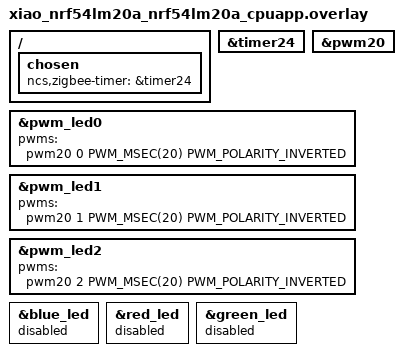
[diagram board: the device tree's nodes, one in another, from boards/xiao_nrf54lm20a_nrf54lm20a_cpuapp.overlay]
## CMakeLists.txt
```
cmake_minimum_required(VERSION 3.20.0)
find_package(Zephyr REQUIRED HINTS $ENV{ZEPHYR_BASE})
project(sustain_zigbee_node)
target_include_directories(app PRIVATE include)
target_sources(app PRIVATE src/main.c src/observation.c src/simulated_source.c
  src/zigbee_transport.c src/board_status.c)
```

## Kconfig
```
mainmenu "Sustain Zigbee test node"
source "Kconfig.zephyr"

config SUSTAIN_REPORT_INTERVAL_SECONDS
	int "Simulated observation interval in seconds"
	range 2 3600
	default 10

config SUSTAIN_STATUS_RGB
	bool "RGB PWM network indicator"
	depends on PWM
	default n

config SUSTAIN_SLEEPY
	bool "Sleepy receiver behavior"
	depends on ZIGBEE_ROLE_END_DEVICE
	default n
```

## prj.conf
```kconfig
CONFIG_ZIGBEE_ADD_ON=y
CONFIG_ZIGBEE_APP_UTILS=y
CONFIG_ZIGBEE_FACTORY_RESET=n
CONFIG_ZIGBEE_CHANNEL_SELECTION_MODE_MULTI=y
CONFIG_ZIGBEE_CHANNEL_MASK=0x07fff800
CONFIG_LTO=y
CONFIG_USE_DT_CODE_PARTITION=y
CONFIG_HEAP_MEM_POOL_SIZE=2048
CONFIG_MAIN_STACK_SIZE=2048
CONFIG_MAIN_THREAD_PRIORITY=7
CONFIG_SYSTEM_WORKQUEUE_STACK_SIZE=2048
CONFIG_LOG=y
CONFIG_LOG_MODE_DEFERRED=y
CONFIG_SERIAL=y
CONFIG_CONSOLE=y
CONFIG_UART_CONSOLE=y
```

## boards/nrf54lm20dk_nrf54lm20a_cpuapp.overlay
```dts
#include <nrf54lm20_cpuapp_partitions.dtsi>
/ { chosen { ncs,zigbee-timer = &timer24; }; };
&timer24 { status = "okay"; };
```

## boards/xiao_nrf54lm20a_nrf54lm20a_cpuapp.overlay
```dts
/* Tested xiao_source mapping: red=CH0/P1.22, blue=CH1/P1.23,
 * green=CH2/P1.24, active low. Pin control is supplied by pinned Seeed BSP.
 * This is a direct-programming development image; no MCUboot/USB DFU.
 */
#include <nrf54lm20_cpuapp_partitions.dtsi>

/* Seeed also declares non-secure upgrade partitions: remove overlaps. */
/delete-node/ &slot0_ns_partition;
/delete-node/ &slot1_ns_partition;

/ {
	chosen { ncs,zigbee-timer = &timer24; };
};
&timer24 { status = "okay"; };
&pwm20 { status = "okay"; };
&pwm_led0 { pwms = <&pwm20 0 PWM_MSEC(20) PWM_POLARITY_INVERTED>; };
&pwm_led1 { pwms = <&pwm20 1 PWM_MSEC(20) PWM_POLARITY_INVERTED>; };
&pwm_led2 { pwms = <&pwm20 2 PWM_MSEC(20) PWM_POLARITY_INVERTED>; };

/* PWM owns these pins; do not let gpio-leds drive the same outputs. */
&blue_led { status = "disabled"; };
&red_led { status = "disabled"; };
&green_led { status = "disabled"; };
```

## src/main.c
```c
/** @file
 * @brief Compose the simulated producer, optional indicator and transport.
 */
#include <zephyr/kernel.h>
#include <zephyr/logging/log.h>
#include "board_status.h"
#include "zigbee_transport.h"

LOG_MODULE_REGISTER(sustain_node, LOG_LEVEL_INF);

int main(void)
{
	int err = board_status_init();
	if (err) {
		LOG_ERR("Status indicator unavailable: %d", err);
		return err;
	}
	LOG_INF("SIMULATED observations; interval=%d s; role=%s",
		CONFIG_SUSTAIN_REPORT_INTERVAL_SECONDS,
		IS_ENABLED(CONFIG_SUSTAIN_SLEEPY) ? "sleepy end device" : "router");
	zigbee_transport_start();
	for (;;) {
		struct observation value = simulated_source_next(
			(uint32_t)(k_uptime_get() / 1000),
			IS_ENABLED(CONFIG_SUSTAIN_SLEEPY) ? 2 : 1);
		err = zigbee_transport_submit(&value);
		LOG_INF("Generated seq=%u simulated=1 enqueue=%d", value.sequence, err);
		k_sleep(K_SECONDS(CONFIG_SUSTAIN_REPORT_INTERVAL_SECONDS));
	}
}
```

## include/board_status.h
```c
/** @file
 * @brief Optional board-profile status indicator, independent of report logic.
 */
#ifndef SUSTAIN_BOARD_STATUS_H
#define SUSTAIN_BOARD_STATUS_H
#include <stdbool.h>
/**
 * @brief Initialize optional PWM indicators and show the unjoined state.
 * @retval 0 Initialization succeeded, or RGB support is disabled.
 * @retval -ENODEV A configured PWM device is unavailable.
 * @return A PWM driver error if a pulse could not be configured.
 */
int board_status_init(void);

/**
 * @brief Update the optional blue/green connection indication.
 * @param joined True for joined (green), false for unjoined (blue).
 * @note No-op without RGB support. PWM update errors are deliberately ignored;
 * this debug indicator does not control commissioning or radio behavior.
 */
void board_status_joined(bool joined);
#endif
```

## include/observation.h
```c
/** @file
 * @brief Portable observation model, simulator and wire encoder.
 */
#ifndef SUSTAIN_OBSERVATION_H
#define SUSTAIN_OBSERVATION_H

#include <stddef.h>
#include <stdint.h>

#define OBSERVATION_WIRE_VERSION 1U /**< Supported wire schema. */
#define OBSERVATION_WIRE_SIZE 16U /**< Encoded record size, without ZCL length. */
#define OBSERVATION_FLAG_SIMULATED 0x01U /**< Data came from a synthetic source. */
#define OBSERVATION_FLAG_ANOMALY 0x02U /**< Producer classified an anomaly. */

/**
 * @brief Application snapshot independent of Zephyr, board and Zigbee types.
 *
 * This is an in-memory model. Use observation_encode() instead of casting it
 * to bytes; C structure layout is not the wire representation.
 */
struct observation {
	uint32_t sequence; /**< Generated counter; restarts at boot and wraps. */
	uint32_t uptime_s; /**< Seconds since boot, modulo 2^32. */
	uint16_t score_milli; /**< 0..1000; not a calibrated probability. */
	uint16_t direction_deg; /**< 0..359; synthetic in the test application. */
	uint8_t flags; /**< Combination of OBSERVATION_FLAG_*; other bits zero. */
	uint8_t role; /**< 1 = powered router; 2 = sleepy end device. */
};

/**
 * @brief Encode a validated snapshot as a fixed-size little-endian v1 record.
 * @param[in] value Snapshot to validate; never retained or modified.
 * @param[out] output Caller-owned buffer of at least OBSERVATION_WIRE_SIZE bytes.
 * @retval 0 Record written, including its zero reserved byte.
 * @retval -EINVAL Null pointer, invalid score/direction/role or reserved flag bits.
 * @note Validation completes before output is written. No heap or radio APIs.
 */
int observation_encode(const struct observation *value,
		       uint8_t output[OBSERVATION_WIRE_SIZE]);

/**
 * @brief Advance the deterministic, single-producer simulated source.
 * @param uptime_s Caller-supplied uptime in seconds.
 * @param role Caller-supplied role; use 1 or 2 for an encodable record.
 * @return New snapshot with simulated flag set; sequence starts at 1.
 * @note Uses a static counter; call from one producer thread. Score is 900 every
 * tenth generated record and 100 otherwise; direction cycles in 15-degree steps.
 */
struct observation simulated_source_next(uint32_t uptime_s, uint8_t role);

#endif
```

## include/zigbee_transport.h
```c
/** @file
 * @brief Application-thread interface to the ZBOSS observation transport.
 */
#ifndef SUSTAIN_ZIGBEE_TRANSPORT_H
#define SUSTAIN_ZIGBEE_TRANSPORT_H
#include "observation.h"
/**
 * @brief Register the endpoint, configure the selected role and enable Zigbee.
 * @note Call once during startup. Uses normal persisted ZBOSS network state;
 * starting does not establish that commissioning or joining has completed.
 */
void zigbee_transport_start(void);

/**
 * @brief Copy a validated observation into the thread-safe latest-value slot.
 * @param[in] value Snapshot to encode; the pointer is not retained.
 * @retval 0 A ZBOSS callback was scheduled; delivery is not guaranteed.
 * @retval -EINVAL The snapshot fails observation_encode() validation.
 * @retval -ENOTCONN Node is not joined; pending data is not updated.
 * @retval -EAGAIN Callback scheduling failed after updating the pending slot.
 * @note Call from an application thread. Packet APIs run only in ZBOSS context.
 * Accepted observations may coalesce while a transmission is in flight. There
 * is no offline history or application acknowledgement. A later periodic
 * submission retries scheduling; no automatic retry timer is installed here.
 */
int zigbee_transport_submit(const struct observation *value);
#endif
```

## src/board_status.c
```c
/** @file
 * @brief Device-tree PWM indicator or no-op implementation selected by profile.
 */
#include "board_status.h"
#include <zephyr/kernel.h>
#if defined(CONFIG_SUSTAIN_STATUS_RGB)
#include <zephyr/drivers/pwm.h>

static const struct pwm_dt_spec red = PWM_DT_SPEC_GET(DT_ALIAS(pwm_led0));
static const struct pwm_dt_spec blue = PWM_DT_SPEC_GET(DT_ALIAS(pwm_led1));
static const struct pwm_dt_spec green = PWM_DT_SPEC_GET(DT_ALIAS(pwm_led2));

int board_status_init(void)
{
	if (!pwm_is_ready_dt(&red) || !pwm_is_ready_dt(&blue) ||
	    !pwm_is_ready_dt(&green)) {
		return -ENODEV;
	}
	int err = pwm_set_pulse_dt(&red, 0);
	if (!err) { err = pwm_set_pulse_dt(&green, 0); }
	if (!err) { err = pwm_set_pulse_dt(&blue, blue.period / 16); }
	return err;
}

void board_status_joined(bool joined)
{
	/* Deliberately dim; this debug indicator is not a power measurement mode. */
	(void)pwm_set_pulse_dt(&blue, joined ? 0 : blue.period / 16);
	(void)pwm_set_pulse_dt(&green, joined ? green.period / 16 : 0);
}
#else
int board_status_init(void) { return 0; }
void board_status_joined(bool joined) { ARG_UNUSED(joined); }
#endif
```

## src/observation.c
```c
/** @file
 * @brief Range validation and explicit byte-wise observation encoding.
 */
#include "observation.h"
#include <errno.h>

static void put16(uint8_t *out, uint16_t value)
{
	out[0] = (uint8_t)value;
	out[1] = (uint8_t)(value >> 8);
}

static void put32(uint8_t *out, uint32_t value)
{
	put16(out, (uint16_t)value);
	put16(out + 2, (uint16_t)(value >> 16));
}

int observation_encode(const struct observation *value,
		       uint8_t output[OBSERVATION_WIRE_SIZE])
{
	if (value == NULL || output == NULL || value->score_milli > 1000 ||
	    value->direction_deg >= 360 || value->role < 1 || value->role > 2 ||
	    (value->flags & ~0x03U) != 0) {
		return -EINVAL;
	}
	output[0] = OBSERVATION_WIRE_VERSION;
	output[1] = value->flags;
	put32(output + 2, value->sequence);
	put32(output + 6, value->uptime_s);
	put16(output + 10, value->score_milli);
	put16(output + 12, value->direction_deg);
	output[14] = value->role;
	output[15] = 0; /* reserved */
	return 0;
}
```

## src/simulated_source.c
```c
/** @file
 * @brief Deterministic test observations; no acoustic input or inference.
 */
#include "observation.h"

struct observation simulated_source_next(uint32_t uptime_s, uint8_t role)
{
	static uint32_t sequence;
	const uint32_t current = ++sequence;
	const uint16_t score = (current % 10U == 0U) ? 900U : 100U;

	return (struct observation) {
		.sequence = current,
		.uptime_s = uptime_s,
		.score_milli = score,
		.direction_deg = (uint16_t)((current % 24U) * 15U),
		.flags = OBSERVATION_FLAG_SIMULATED |
			 ((score >= 800U) ? OBSERVATION_FLAG_ANOMALY : 0U),
		.role = role,
	};
}
```

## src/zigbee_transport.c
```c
/** @file
 * @brief ZBOSS endpoint registration, report scheduling and buffer ownership.
 *
 * Application threads encode into a spinlock-protected pending slot. ZBOSS
 * callbacks own in_flight, allocate the outgoing buffer and free it after
 * completion or immediate rejection. No persistent event queue is implemented.
 */
#include <errno.h>
#include <string.h>
#include <zephyr/kernel.h>
#include <zephyr/logging/log.h>
#include <zephyr/sys/atomic.h>
#include <zboss_api.h>
#include <zb_nrf_platform.h>
#include <zigbee/zigbee_app_utils.h>
#include "board_status.h"
#include "zigbee_transport.h"

LOG_MODULE_REGISTER(sustain_zigbee, LOG_LEVEL_INF);

#define NODE_ENDPOINT 10
#define OBS_CLUSTER 0xfc00
#define OBS_ATTRIBUTE 0x0000
/* This private cluster uses generic read/discover commands only. */
#define OBS_CLUSTER_SERVER_ROLE_INIT NULL
#define OBS_CLUSTER_CLIENT_ROLE_INIT NULL

static zb_uint8_t zcl_version = ZB_ZCL_VERSION;
static zb_uint8_t power_source;
static zb_uint16_t identify_time;
static zb_char_t manufacturer[] = "\x07" "Sustain";
static zb_char_t model[] = "\x0e" "SustainNode-v1";
/* Octet string: ZCL length byte followed by the versioned wire record. */
static zb_uint8_t observation_attr[1 + OBSERVATION_WIRE_SIZE] = { OBSERVATION_WIRE_SIZE };
static uint8_t pending[OBSERVATION_WIRE_SIZE];
static struct k_spinlock pending_lock;
static atomic_t joined;
static bool in_flight; /* Only touched in ZBOSS context. */

ZB_ZCL_START_DECLARE_ATTRIB_LIST(basic_attrs)
 ZB_ZCL_SET_ATTR_DESC(ZB_ZCL_ATTR_BASIC_ZCL_VERSION_ID, &zcl_version)
 ZB_ZCL_SET_ATTR_DESC(ZB_ZCL_ATTR_BASIC_POWER_SOURCE_ID, &power_source)
 ZB_ZCL_SET_ATTR_DESC(ZB_ZCL_ATTR_BASIC_MANUFACTURER_NAME_ID, manufacturer)
 ZB_ZCL_SET_ATTR_DESC(ZB_ZCL_ATTR_BASIC_MODEL_IDENTIFIER_ID, model)
ZB_ZCL_FINISH_DECLARE_ATTRIB_LIST;

ZB_ZCL_DECLARE_IDENTIFY_ATTRIB_LIST(identify_attrs, &identify_time);

ZB_ZCL_START_DECLARE_ATTRIB_LIST(obs_attrs)
 ZB_ZCL_SET_ATTR_DESC_M(OBS_ATTRIBUTE, observation_attr, ZB_ZCL_ATTR_TYPE_OCTET_STRING,
                       ZB_ZCL_ATTR_ACCESS_READ_ONLY)
ZB_ZCL_FINISH_DECLARE_ATTRIB_LIST;

static zb_zcl_cluster_desc_t clusters[] = {
	ZB_ZCL_CLUSTER_DESC(ZB_ZCL_CLUSTER_ID_BASIC, ZB_ZCL_ARRAY_SIZE(basic_attrs, zb_zcl_attr_t),
		basic_attrs, ZB_ZCL_CLUSTER_SERVER_ROLE, ZB_ZCL_MANUF_CODE_INVALID),
	ZB_ZCL_CLUSTER_DESC(ZB_ZCL_CLUSTER_ID_IDENTIFY, ZB_ZCL_ARRAY_SIZE(identify_attrs, zb_zcl_attr_t),
		identify_attrs, ZB_ZCL_CLUSTER_SERVER_ROLE, ZB_ZCL_MANUF_CODE_INVALID),
	ZB_ZCL_CLUSTER_DESC(OBS_CLUSTER, ZB_ZCL_ARRAY_SIZE(obs_attrs, zb_zcl_attr_t),
		obs_attrs, ZB_ZCL_CLUSTER_SERVER_ROLE, ZB_ZCL_MANUF_CODE_INVALID),
};

ZB_DECLARE_SIMPLE_DESC(3, 0);
static ZB_AF_SIMPLE_DESC_TYPE(3, 0) simple_desc = {
	NODE_ENDPOINT, ZB_AF_HA_PROFILE_ID, ZB_HA_CUSTOM_ATTR_DEVICE_ID, 1, 0, 3, 0,
	{ ZB_ZCL_CLUSTER_ID_BASIC, ZB_ZCL_CLUSTER_ID_IDENTIFY, OBS_CLUSTER }
};
ZB_AF_DECLARE_ENDPOINT_DESC(node_ep, NODE_ENDPOINT, ZB_AF_HA_PROFILE_ID, 0, NULL,
	ZB_ZCL_ARRAY_SIZE(clusters, zb_zcl_cluster_desc_t), clusters,
	(zb_af_simple_desc_1_1_t *)&simple_desc, 0, NULL, 0, NULL);
ZBOSS_DECLARE_DEVICE_CTX_1_EP(node_ctx, node_ep);

static void report_complete(zb_bufid_t buffer)
{
	zb_zcl_command_send_status_t *status =
		ZB_BUF_GET_PARAM(buffer, zb_zcl_command_send_status_t);
	LOG_INF("Report APS completion status=%d", status->status);
	in_flight = false;
	zb_buf_free(buffer);
}

static void send_report(zb_bufid_t buffer)
{
	if (!ZB_JOINED()) {
		in_flight = false;
		zb_buf_free(buffer);
		return;
	}
	k_spinlock_key_t key = k_spin_lock(&pending_lock);
	memcpy(observation_attr + 1, pending, sizeof(pending));
	k_spin_unlock(&pending_lock, key);

	zb_uint8_t *ptr = ZB_ZCL_START_PACKET(buffer);
	ZB_ZCL_CONSTRUCT_GENERAL_COMMAND_REQ_FRAME_CONTROL_A(ptr,
		ZB_ZCL_FRAME_DIRECTION_TO_CLI, ZB_ZCL_NOT_MANUFACTURER_SPECIFIC,
		ZB_ZCL_DISABLE_DEFAULT_RESPONSE);
	ZB_ZCL_CONSTRUCT_COMMAND_HEADER(ptr, ZB_ZCL_GET_SEQ_NUM(), ZB_ZCL_CMD_REPORT_ATTRIB);
	ZB_ZCL_PACKET_PUT_DATA16_VAL(ptr, OBS_ATTRIBUTE);
	ZB_ZCL_PACKET_PUT_DATA8(ptr, ZB_ZCL_ATTR_TYPE_OCTET_STRING);
	for (size_t i = 0; i < sizeof(observation_attr); ++i) {
		ZB_ZCL_PACKET_PUT_DATA8(ptr, observation_attr[i]);
	}
	/* Bench contract: coordinator short address 0, HA endpoint 1.
	 * Explicit periodic reports avoid binding/configure-report dependencies.
	 */
	zb_addr_u destination = { .addr_short = 0x0000 };
	zb_ret_t result = zb_zcl_finish_and_send_packet(buffer, ptr, &destination,
		ZB_APS_ADDR_MODE_16_ENDP_PRESENT, 1, NODE_ENDPOINT,
		ZB_AF_HA_PROFILE_ID, OBS_CLUSTER, report_complete);
	if (result != RET_OK) {
		LOG_WRN("Report rejected: %d", result);
		in_flight = false;
		zb_buf_free(buffer);
	}
}

static void request_report(zb_uint8_t unused)
{
	ARG_UNUSED(unused);
	if (in_flight || !ZB_JOINED()) { return; }
	in_flight = true;
	if (zb_buf_get_out_delayed(send_report) != RET_OK) {
		in_flight = false;
		LOG_WRN("No output buffer; latest observation waits for next interval");
	}
}

int zigbee_transport_submit(const struct observation *value)
{
	uint8_t encoded[OBSERVATION_WIRE_SIZE];
	int err = observation_encode(value, encoded);
	if (err) { return err; }
	if (!atomic_get(&joined)) { return -ENOTCONN; }
	k_spinlock_key_t key = k_spin_lock(&pending_lock);
	memcpy(pending, encoded, sizeof(pending));
	k_spin_unlock(&pending_lock, key);
	return ZB_SCHEDULE_APP_CALLBACK(request_report, 0) == RET_OK ? 0 : -EAGAIN;
}

void zboss_signal_handler(zb_bufid_t buffer)
{
	zb_ret_t result = zigbee_default_signal_handler(buffer);
	if (result != RET_OK) { LOG_WRN("Default signal handler: %d", result); }
	bool connected = ZB_JOINED();
	atomic_set(&joined, connected);
	board_status_joined(connected);
	LOG_INF("Network joined=%d", connected);
	if (buffer) { zb_buf_free(buffer); }
}

void zigbee_transport_start(void)
{
	/* USB-powered bench devices report DC power, including the SED profile. */
	power_source = ZB_ZCL_BASIC_POWER_SOURCE_DC_SOURCE;
	ZB_AF_REGISTER_DEVICE_CTX(&node_ctx);
	if (IS_ENABLED(CONFIG_SUSTAIN_SLEEPY)) {
#if defined(CONFIG_ZIGBEE_ROLE_END_DEVICE)
		zb_set_keepalive_timeout(ZB_MILLISECONDS_TO_BEACON_INTERVAL(3000));
		zigbee_configure_sleepy_behavior(true);
#endif
	}
	zigbee_enable(); /* Retain normal ZBOSS NVRAM/rejoin behavior. */
}
```
